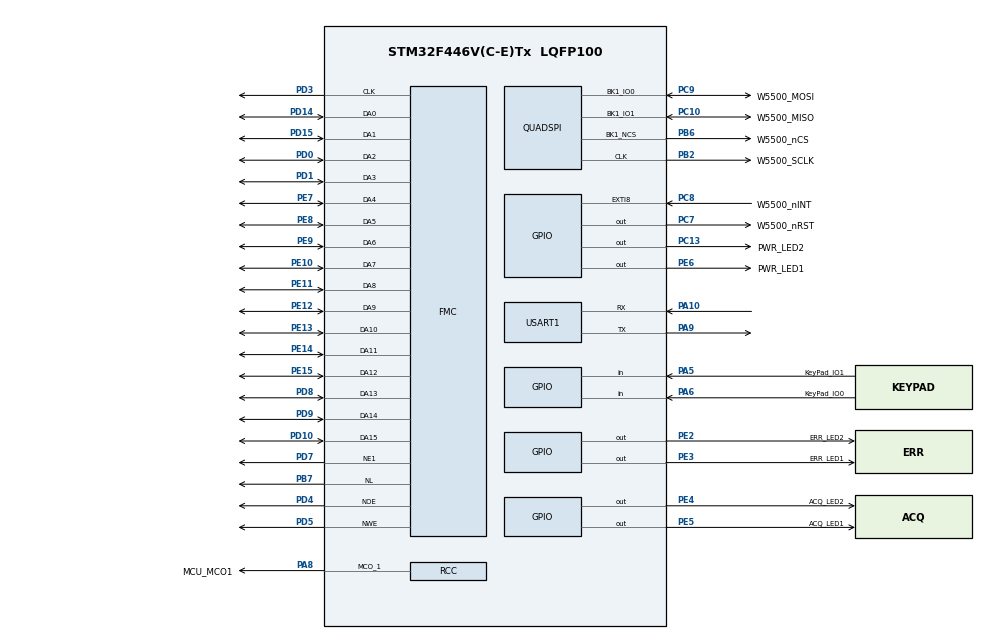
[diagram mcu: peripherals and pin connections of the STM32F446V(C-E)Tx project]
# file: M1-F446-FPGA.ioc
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Dma.MEMTOMEM.0.Direction=DMA_MEMORY_TO_MEMORY
Dma.MEMTOMEM.0.FIFOMode=DMA_FIFOMODE_ENABLE
Dma.MEMTOMEM.0.FIFOThreshold=DMA_FIFO_THRESHOLD_FULL
Dma.MEMTOMEM.0.Instance=DMA2_Stream0
Dma.MEMTOMEM.0.MemBurst=DMA_MBURST_INC8
Dma.MEMTOMEM.0.MemDataAlignment=DMA_MDATAALIGN_HALFWORD
Dma.MEMTOMEM.0.MemInc=DMA_MINC_ENABLE
Dma.MEMTOMEM.0.Mode=DMA_NORMAL
Dma.MEMTOMEM.0.PeriphBurst=DMA_PBURST_INC8
Dma.MEMTOMEM.0.PeriphDataAlignment=DMA_PDATAALIGN_HALFWORD
Dma.MEMTOMEM.0.PeriphInc=DMA_PINC_ENABLE
Dma.MEMTOMEM.0.Priority=DMA_PRIORITY_HIGH
Dma.MEMTOMEM.1.Direction=DMA_MEMORY_TO_MEMORY
Dma.MEMTOMEM.1.FIFOMode=DMA_FIFOMODE_ENABLE
Dma.MEMTOMEM.1.FIFOThreshold=DMA_FIFO_THRESHOLD_FULL
Dma.MEMTOMEM.1.Instance=DMA2_Stream1
Dma.MEMTOMEM.1.MemBurst=DMA_MBURST_INC8
Dma.MEMTOMEM.1.MemDataAlignment=DMA_MDATAALIGN_HALFWORD
Dma.MEMTOMEM.1.MemInc=DMA_MINC_ENABLE
Dma.MEMTOMEM.1.Mode=DMA_NORMAL
Dma.MEMTOMEM.1.PeriphBurst=DMA_PBURST_INC8
Dma.MEMTOMEM.1.PeriphDataAlignment=DMA_PDATAALIGN_HALFWORD
Dma.MEMTOMEM.1.PeriphInc=DMA_PINC_ENABLE
Dma.MEMTOMEM.1.Priority=DMA_PRIORITY_HIGH
Dma.QUADSPI.2.Direction=DMA_MEMORY_TO_PERIPH
Dma.QUADSPI.2.FIFOMode=DMA_FIFOMODE_DISABLE
Dma.QUADSPI.2.Instance=DMA2_Stream7
Dma.QUADSPI.2.MemDataAlignment=DMA_MDATAALIGN_BYTE
Dma.QUADSPI.2.MemInc=DMA_MINC_ENABLE
Dma.QUADSPI.2.Mode=DMA_NORMAL
Dma.QUADSPI.2.PeriphDataAlignment=DMA_PDATAALIGN_BYTE
Dma.QUADSPI.2.PeriphInc=DMA_PINC_DISABLE
Dma.QUADSPI.2.Priority=DMA_PRIORITY_LOW
Dma.Request0=MEMTOMEM
Dma.Request1=MEMTOMEM
Dma.Request2=QUADSPI
FMC.BusTurnAroundDuration1=4
FMC.CLKDivision1=2
FMC.WriteOperation1=FMC_WRITE_OPERATION_ENABLE
Mcu.Family=STM32F4
Mcu.Name=STM32F446V(C-E)Tx
Mcu.Package=LQFP100
NVIC.PriorityGroup=NVIC_PRIORITYGROUP_4
PA10.Mode=Asynchronous
PA10.Signal=USART1_RX
PA5.GPIO_Label=KeyPad_IO1
PA5.Signal=GPIO_Input
PA6.GPIO_Label=KeyPad_IO0
PA6.Signal=GPIO_Input
PA8.GPIO_Label=MCU_MCO1
PA8.GPIO_Speed=GPIO_SPEED_FREQ_HIGH
PA8.Mode=Clock-out-1
PA8.Signal=RCC_MCO_1
PA9.Mode=Asynchronous
PA9.Signal=USART1_TX
PB2.GPIO_Label=W5500_SCLK
PB2.Mode=Single Bank 1 2IOs
PB2.Signal=QUADSPI_CLK
PB6.GPIO_Label=W5500_nCS
PB6.Mode=Single Bank 1 2IOs
PB6.Signal=QUADSPI_BK1_NCS
PB7.Signal=FMC_NL
PC10.GPIO_Label=W5500_MISO
PC10.Mode=Single Bank 1 2IOs
PC10.Signal=QUADSPI_BK1_IO1
PC13.GPIO_Label=PWR_LED2
PC13.Signal=GPIO_Output
PC14-OSC32_IN.Mode=LSE-External-Oscillator
PC14-OSC32_IN.Signal=RCC_OSC32_IN
PC15-OSC32_OUT.Mode=LSE-External-Oscillator
PC15-OSC32_OUT.Signal=RCC_OSC32_OUT
PC7.GPIO_Label=W5500_nRST
PC7.PinState=GPIO_PIN_SET
PC7.Signal=GPIO_Output
PC8.GPIO_Label=W5500_nINT
PC8.GPIO_ModeDefaultEXTI=GPIO_MODE_IT_FALLING
PC8.Signal=GPXTI8
PC9.GPIO_Label=W5500_MOSI
PC9.Mode=Single Bank 1 2IOs
PC9.Signal=QUADSPI_BK1_IO0
PD0.Mode=16b-da1
PD0.Signal=FMC_DA2
PD1.Mode=16b-da1
PD1.Signal=FMC_DA3
PD10.Mode=16b-da1
PD10.Signal=FMC_DA15
PD14.Mode=16b-da1
PD14.Signal=FMC_DA0
PD15.Mode=16b-da1
PD15.Signal=FMC_DA1
PD3.Mode=BurstReadWrite1
PD3.Signal=FMC_CLK
PD4.Mode=MuxedPsram1
PD4.Signal=FMC_NOE
PD5.Mode=MuxedPsram1
PD5.Signal=FMC_NWE
PD7.Mode=NorPsramChipSelect1_1
PD7.Signal=FMC_NE1
PD8.Mode=16b-da1
PD8.Signal=FMC_DA13
PD9.Mode=16b-da1
PD9.Signal=FMC_DA14
PE10.Mode=16b-da1
PE10.Signal=FMC_DA7
PE11.Mode=16b-da1
PE11.Signal=FMC_DA8
PE12.Mode=16b-da1
PE12.Signal=FMC_DA9
PE13.Mode=16b-da1
PE13.Signal=FMC_DA10
PE14.Mode=16b-da1
PE14.Signal=FMC_DA11
PE15.Mode=16b-da1
PE15.Signal=FMC_DA12
PE2.GPIO_Label=ERR_LED2
PE2.Signal=GPIO_Output
PE3.GPIO_Label=ERR_LED1
PE3.Signal=GPIO_Output
PE4.GPIO_Label=ACQ_LED2
PE4.Signal=GPIO_Output
PE5.GPIO_Label=ACQ_LED1
PE5.Signal=GPIO_Output
PE6.GPIO_Label=PWR_LED1
PE6.Signal=GPIO_Output
PE7.Mode=16b-da1
PE7.Signal=FMC_DA4
PE8.Mode=16b-da1
PE8.Signal=FMC_DA5
PE9.Mode=16b-da1
PE9.Signal=FMC_DA6
PH0-OSC_IN.Mode=HSE-External-Oscillator
PH0-OSC_IN.Signal=RCC_OSC_IN
PH1-OSC_OUT.Mode=HSE-External-Oscillator
PH1-OSC_OUT.Signal=RCC_OSC_OUT
ProjectManager.HeapSize=0x200
ProjectManager.StackSize=0x400
ProjectManager.TargetToolchain=MDK-ARM V5.27
QUADSPI.ChipSelectHighTime=QSPI_CS_HIGH_TIME_4_CYCLE
QUADSPI.ClockPrescaler=3
QUADSPI.FifoThreshold=9
QUADSPI.FlashSize=16
RCC.AHBFreq_Value=160000000
RCC.APB1CLKDivider=RCC_HCLK_DIV4
RCC.APB1Freq_Value=40000000
RCC.APB1TimFreq_Value=80000000
RCC.APB2CLKDivider=RCC_HCLK_DIV2
RCC.APB2Freq_Value=80000000
RCC.APB2TimFreq_Value=160000000
RCC.CortexFreq_Value=160000000
RCC.HCLKFreq_Value=160000000
RCC.HSE_VALUE=16000000
RCC.PLLN=320
RCC.PLLSourceVirtual=RCC_PLLSOURCE_HSE
RCC.RCC_TIM_PRescaler_Selection=RCC_TIMPRES_DESACTIVATED
RCC.SYSCLKFreq_VALUE=160000000
RCC.SYSCLKSource=RCC_SYSCLKSOURCE_PLLCLK
RCC.USBFreq_Value=160000000
RCC.VCOOutputFreq_Value=320000000
SH.FMC_NL.0=FMC_NL,AddressValid1
USART1.VirtualMode=VM_ASYNC
board=custom

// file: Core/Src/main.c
/* USER CODE BEGIN Header */
/**
  ******************************************************************************
  * @file           : main.c
  * @brief          : Main program body
  ******************************************************************************
  * @attention
  *
  * <h2><center>&copy; Copyright (c) 2022 STMicroelectronics.
  * All rights reserved.</center></h2>
  *
  * This software component is licensed by ST under BSD 3-Clause license,
  * the "License"; You may not use this file except in compliance with the
  * License. You may obtain a copy of the License at:
  *                        opensource.org/licenses/BSD-3-Clause
  *
  ******************************************************************************
  */
/* USER CODE END Header */
#include "main.h"

/* USER CODE BEGIN Includes */
#include "w5500_service.h"
/* USER CODE END Includes */

QSPI_HandleTypeDef hqspi;
DMA_HandleTypeDef hdma_quadspi;

SRAM_HandleTypeDef hsram1;

/* USER CODE BEGIN PV */
uint32_t SYS_Event;							//!< 系统状态事件
/* USER CODE END PV */

void SystemClock_Config(void);
static void MX_GPIO_Init(void);
static void MX_DMA_Init(void);
static void MX_FMC_Init(void);
static void MX_USART1_UART_Init(void);
static void MX_QUADSPI_Init(void);

int main(void)
{

  /* MCU Configuration--------------------------------------------------------*/

  /* Reset of all peripherals, Initializes the Flash interface and the Systick. */
  HAL_Init();

  /* Configure the system clock */
  SystemClock_Config();

  /* Initialize all configured peripherals */
  MX_GPIO_Init();
  MX_DMA_Init();
  MX_FMC_Init();
  MX_USART1_UART_Init();
  MX_QUADSPI_Init();
  /* USER CODE BEGIN 2 */

	PWR_LED1_ON;	//设备通电状态指示
	PWR_LED2_OFF;
	ACQ_LED1_OFF; //设备采样状态指示
	ACQ_LED2_OFF; //设备事件接收指示 （收发完成一次亮灭）
	ERR_LED1_OFF;
	ERR_LED2_OFF; //设备运行状态指示
	W5500_Init(); //W5500初始化，配置Socket
  /* USER CODE END 2 */

  /* Infinite loop */
  while (1)
  {

  }
}

void SystemClock_Config(void)
{
  LL_FLASH_SetLatency(LL_FLASH_LATENCY_5);
  while(LL_FLASH_GetLatency()!= LL_FLASH_LATENCY_5)
  {
  }
  LL_PWR_SetRegulVoltageScaling(LL_PWR_REGU_VOLTAGE_SCALE1);
  LL_PWR_DisableOverDriveMode();
  LL_RCC_HSE_Enable();

   /* Wait till HSE is ready */
  while(LL_RCC_HSE_IsReady() != 1)
  {

  }
  LL_RCC_HSI_SetCalibTrimming(16);
  LL_RCC_HSI_Enable();

   /* Wait till HSI is ready */
  while(LL_RCC_HSI_IsReady() != 1)
  {

  }
  LL_RCC_PLL_ConfigDomain_SYS(LL_RCC_PLLSOURCE_HSE, LL_RCC_PLLM_DIV_16, 320, LL_RCC_PLLP_DIV_2);
  LL_RCC_PLL_Enable();

   /* Wait till PLL is ready */
  while(LL_RCC_PLL_IsReady() != 1)
  {

  }
  LL_RCC_SetAHBPrescaler(LL_RCC_SYSCLK_DIV_1);
  LL_RCC_SetAPB1Prescaler(LL_RCC_APB1_DIV_4);
  LL_RCC_SetAPB2Prescaler(LL_RCC_APB2_DIV_2);
  LL_RCC_SetSysClkSource(LL_RCC_SYS_CLKSOURCE_PLL);

   /* Wait till System clock is ready */
  while(LL_RCC_GetSysClkSource() != LL_RCC_SYS_CLKSOURCE_STATUS_PLL)
  {

  }
  LL_SetSystemCoreClock(160000000);

   /* Update the time base */
  if (HAL_InitTick (TICK_INT_PRIORITY) != HAL_OK)
  {
    Error_Handler();
  }
  LL_RCC_ConfigMCO(LL_RCC_MCO1SOURCE_HSI, LL_RCC_MCO1_DIV_1);
  LL_RCC_SetTIMPrescaler(LL_RCC_TIM_PRESCALER_TWICE);
}

static void MX_QUADSPI_Init(void)
{

  /* QUADSPI parameter configuration*/
  hqspi.Instance = QUADSPI;
  hqspi.Init.ClockPrescaler = 3;
  hqspi.Init.FifoThreshold = 9;
  hqspi.Init.SampleShifting = QSPI_SAMPLE_SHIFTING_NONE;
  hqspi.Init.FlashSize = 16;
  hqspi.Init.ChipSelectHighTime = QSPI_CS_HIGH_TIME_4_CYCLE;
  hqspi.Init.ClockMode = QSPI_CLOCK_MODE_0;
  hqspi.Init.FlashID = QSPI_FLASH_ID_1;
  hqspi.Init.DualFlash = QSPI_DUALFLASH_DISABLE;
  if (HAL_QSPI_Init(&hqspi) != HAL_OK)
  {
    Error_Handler();
  }

}

static void MX_USART1_UART_Init(void)
{

  LL_USART_InitTypeDef USART_InitStruct = {0};

  LL_GPIO_InitTypeDef GPIO_InitStruct = {0};

  /* Peripheral clock enable */
  LL_APB2_GRP1_EnableClock(LL_APB2_GRP1_PERIPH_USART1);

  LL_AHB1_GRP1_EnableClock(LL_AHB1_GRP1_PERIPH_GPIOA);
  /**USART1 GPIO Configuration
  PA9   ------> USART1_TX
  PA10   ------> USART1_RX
  */
  GPIO_InitStruct.Pin = LL_GPIO_PIN_9|LL_GPIO_PIN_10;
  GPIO_InitStruct.Mode = LL_GPIO_MODE_ALTERNATE;
  GPIO_InitStruct.Speed = LL_GPIO_SPEED_FREQ_VERY_HIGH;
  GPIO_InitStruct.OutputType = LL_GPIO_OUTPUT_PUSHPULL;
  GPIO_InitStruct.Pull = LL_GPIO_PULL_NO;
  GPIO_InitStruct.Alternate = LL_GPIO_AF_7;
  LL_GPIO_Init(GPIOA, &GPIO_InitStruct);

  USART_InitStruct.BaudRate = 115200;
  USART_InitStruct.DataWidth = LL_USART_DATAWIDTH_8B;
  USART_InitStruct.StopBits = LL_USART_STOPBITS_1;
  USART_InitStruct.Parity = LL_USART_PARITY_NONE;
  USART_InitStruct.TransferDirection = LL_USART_DIRECTION_TX_RX;
  USART_InitStruct.HardwareFlowControl = LL_USART_HWCONTROL_NONE;
  USART_InitStruct.OverSampling = LL_USART_OVERSAMPLING_16;
  LL_USART_Init(USART1, &USART_InitStruct);
  LL_USART_ConfigAsyncMode(USART1);
  LL_USART_Enable(USART1);

}

static void MX_DMA_Init(void)
{

  /* Init with LL driver */
  /* DMA controller clock enable */
  LL_AHB1_GRP1_EnableClock(LL_AHB1_GRP1_PERIPH_DMA2);

  /* Configure DMA request MEMTOMEM_DMA2_Stream0 */

  /* Select channel */
  LL_DMA_SetChannelSelection(DMA2, LL_DMA_STREAM_0, LL_DMA_CHANNEL_0);

  /* Set transfer direction */
  LL_DMA_SetDataTransferDirection(DMA2, LL_DMA_STREAM_0, LL_DMA_DIRECTION_MEMORY_TO_MEMORY);

  /* Set priority level */
  LL_DMA_SetStreamPriorityLevel(DMA2, LL_DMA_STREAM_0, LL_DMA_PRIORITY_HIGH);

  /* Set DMA mode */
  LL_DMA_SetMode(DMA2, LL_DMA_STREAM_0, LL_DMA_MODE_NORMAL);

  /* Set peripheral increment mode */
  LL_DMA_SetPeriphIncMode(DMA2, LL_DMA_STREAM_0, LL_DMA_PERIPH_INCREMENT);

  /* Set memory increment mode */
  LL_DMA_SetMemoryIncMode(DMA2, LL_DMA_STREAM_0, LL_DMA_MEMORY_INCREMENT);

  /* Set peripheral data width */
  LL_DMA_SetPeriphSize(DMA2, LL_DMA_STREAM_0, LL_DMA_PDATAALIGN_HALFWORD);

  /* Set memory data width */
  LL_DMA_SetMemorySize(DMA2, LL_DMA_STREAM_0, LL_DMA_MDATAALIGN_HALFWORD);

  /* Enable FIFO mode */
  LL_DMA_EnableFifoMode(DMA2, LL_DMA_STREAM_0);

  /* Set FIFO threshold */
  LL_DMA_SetFIFOThreshold(DMA2, LL_DMA_STREAM_0, LL_DMA_FIFOTHRESHOLD_FULL);

  /* Set memory burst size */
  LL_DMA_SetMemoryBurstxfer(DMA2, LL_DMA_STREAM_0, LL_DMA_MBURST_INC8);

  /* Set peripheral burst size */
  LL_DMA_SetPeriphBurstxfer(DMA2, LL_DMA_STREAM_0, LL_DMA_PBURST_INC8);

  /* Configure DMA request MEMTOMEM_DMA2_Stream1 */

  /* Select channel */
  LL_DMA_SetChannelSelection(DMA2, LL_DMA_STREAM_1, LL_DMA_CHANNEL_0);

  /* Set transfer direction */
  LL_DMA_SetDataTransferDirection(DMA2, LL_DMA_STREAM_1, LL_DMA_DIRECTION_MEMORY_TO_MEMORY);

  /* Set priority level */
  LL_DMA_SetStreamPriorityLevel(DMA2, LL_DMA_STREAM_1, LL_DMA_PRIORITY_HIGH);

  /* Set DMA mode */
  LL_DMA_SetMode(DMA2, LL_DMA_STREAM_1, LL_DMA_MODE_NORMAL);

  /* Set peripheral increment mode */
  LL_DMA_SetPeriphIncMode(DMA2, LL_DMA_STREAM_1, LL_DMA_PERIPH_INCREMENT);

  /* Set memory increment mode */
  LL_DMA_SetMemoryIncMode(DMA2, LL_DMA_STREAM_1, LL_DMA_MEMORY_INCREMENT);

  /* Set peripheral data width */
  LL_DMA_SetPeriphSize(DMA2, LL_DMA_STREAM_1, LL_DMA_PDATAALIGN_HALFWORD);

  /* Set memory data width */
  LL_DMA_SetMemorySize(DMA2, LL_DMA_STREAM_1, LL_DMA_MDATAALIGN_HALFWORD);

  /* Enable FIFO mode */
  LL_DMA_EnableFifoMode(DMA2, LL_DMA_STREAM_1);

  /* Set FIFO threshold */
  LL_DMA_SetFIFOThreshold(DMA2, LL_DMA_STREAM_1, LL_DMA_FIFOTHRESHOLD_FULL);

  /* Set memory burst size */
  LL_DMA_SetMemoryBurstxfer(DMA2, LL_DMA_STREAM_1, LL_DMA_MBURST_INC8);

  /* Set peripheral burst size */
  LL_DMA_SetPeriphBurstxfer(DMA2, LL_DMA_STREAM_1, LL_DMA_PBURST_INC8);

}

/* FMC initialization function */
static void MX_FMC_Init(void)
{

  FMC_NORSRAM_TimingTypeDef Timing = {0};

  /** Perform the SRAM1 memory initialization sequence
  */
  hsram1.Instance = FMC_NORSRAM_DEVICE;
  hsram1.Extended = FMC_NORSRAM_EXTENDED_DEVICE;
  /* hsram1.Init */
  hsram1.Init.NSBank = FMC_NORSRAM_BANK1;
  hsram1.Init.DataAddressMux = FMC_DATA_ADDRESS_MUX_ENABLE;
  hsram1.Init.MemoryType = FMC_MEMORY_TYPE_PSRAM;
  hsram1.Init.MemoryDataWidth = FMC_NORSRAM_MEM_BUS_WIDTH_16;
  hsram1.Init.BurstAccessMode = FMC_BURST_ACCESS_MODE_ENABLE;
  hsram1.Init.WaitSignalPolarity = FMC_WAIT_SIGNAL_POLARITY_LOW;
  hsram1.Init.WaitSignalActive = FMC_WAIT_TIMING_BEFORE_WS;
  hsram1.Init.WriteOperation = FMC_WRITE_OPERATION_ENABLE;
  hsram1.Init.WaitSignal = FMC_WAIT_SIGNAL_DISABLE;
  hsram1.Init.ExtendedMode = FMC_EXTENDED_MODE_DISABLE;
  hsram1.Init.AsynchronousWait = FMC_ASYNCHRONOUS_WAIT_DISABLE;
  hsram1.Init.WriteBurst = FMC_WRITE_BURST_ENABLE;
  hsram1.Init.ContinuousClock = FMC_CONTINUOUS_CLOCK_SYNC_ONLY;
  hsram1.Init.WriteFifo = FMC_WRITE_FIFO_ENABLE;
  hsram1.Init.PageSize = FMC_PAGE_SIZE_NONE;
  /* Timing */
  Timing.AddressSetupTime = 15;
  Timing.AddressHoldTime = 15;
  Timing.DataSetupTime = 255;
  Timing.BusTurnAroundDuration = 4;
  Timing.CLKDivision = 2;
  Timing.DataLatency = 2;
  Timing.AccessMode = FMC_ACCESS_MODE_A;
  /* ExtTiming */

  if (HAL_SRAM_Init(&hsram1, &Timing, NULL) != HAL_OK)
  {
    Error_Handler( );
  }

}

static void MX_GPIO_Init(void)
{
  LL_EXTI_InitTypeDef EXTI_InitStruct = {0};
  LL_GPIO_InitTypeDef GPIO_InitStruct = {0};

  /* GPIO Ports Clock Enable */
  LL_AHB1_GRP1_EnableClock(LL_AHB1_GRP1_PERIPH_GPIOE);
  LL_AHB1_GRP1_EnableClock(LL_AHB1_GRP1_PERIPH_GPIOC);
  LL_AHB1_GRP1_EnableClock(LL_AHB1_GRP1_PERIPH_GPIOH);
  LL_AHB1_GRP1_EnableClock(LL_AHB1_GRP1_PERIPH_GPIOA);
  LL_AHB1_GRP1_EnableClock(LL_AHB1_GRP1_PERIPH_GPIOB);
  LL_AHB1_GRP1_EnableClock(LL_AHB1_GRP1_PERIPH_GPIOD);

  /**/
  LL_GPIO_ResetOutputPin(GPIOE, ERR_LED2_Pin|ERR_LED1_Pin|ACQ_LED2_Pin|ACQ_LED1_Pin
                          |PWR_LED1_Pin);

  /**/
  LL_GPIO_ResetOutputPin(PWR_LED2_GPIO_Port, PWR_LED2_Pin);

  /**/
  LL_GPIO_SetOutputPin(W5500_nRST_GPIO_Port, W5500_nRST_Pin);

  /**/
  GPIO_InitStruct.Pin = ERR_LED2_Pin|ERR_LED1_Pin|ACQ_LED2_Pin|ACQ_LED1_Pin
                          |PWR_LED1_Pin;
  GPIO_InitStruct.Mode = LL_GPIO_MODE_OUTPUT;
  GPIO_InitStruct.Speed = LL_GPIO_SPEED_FREQ_LOW;
  GPIO_InitStruct.OutputType = LL_GPIO_OUTPUT_PUSHPULL;
  GPIO_InitStruct.Pull = LL_GPIO_PULL_NO;
  LL_GPIO_Init(GPIOE, &GPIO_InitStruct);

  /**/
  GPIO_InitStruct.Pin = PWR_LED2_Pin|W5500_nRST_Pin;
  GPIO_InitStruct.Mode = LL_GPIO_MODE_OUTPUT;
  GPIO_InitStruct.Speed = LL_GPIO_SPEED_FREQ_LOW;
  GPIO_InitStruct.OutputType = LL_GPIO_OUTPUT_PUSHPULL;
  GPIO_InitStruct.Pull = LL_GPIO_PULL_NO;
  LL_GPIO_Init(GPIOC, &GPIO_InitStruct);

  /**/
  GPIO_InitStruct.Pin = KeyPad_IO1_Pin|KeyPad_IO0_Pin;
  GPIO_InitStruct.Mode = LL_GPIO_MODE_INPUT;
  GPIO_InitStruct.Pull = LL_GPIO_PULL_NO;
  LL_GPIO_Init(GPIOA, &GPIO_InitStruct);

  /**/
  GPIO_InitStruct.Pin = MCU_MCO1_Pin;
  GPIO_InitStruct.Mode = LL_GPIO_MODE_ALTERNATE;
  GPIO_InitStruct.Speed = LL_GPIO_SPEED_FREQ_HIGH;
  GPIO_InitStruct.OutputType = LL_GPIO_OUTPUT_PUSHPULL;
  GPIO_InitStruct.Pull = LL_GPIO_PULL_NO;
  GPIO_InitStruct.Alternate = LL_GPIO_AF_0;
  LL_GPIO_Init(MCU_MCO1_GPIO_Port, &GPIO_InitStruct);

  /**/
  LL_SYSCFG_SetEXTISource(LL_SYSCFG_EXTI_PORTC, LL_SYSCFG_EXTI_LINE8);

  /**/
  EXTI_InitStruct.Line_0_31 = LL_EXTI_LINE_8;
  EXTI_InitStruct.LineCommand = ENABLE;
  EXTI_InitStruct.Mode = LL_EXTI_MODE_IT;
  EXTI_InitStruct.Trigger = LL_EXTI_TRIGGER_FALLING;
  LL_EXTI_Init(&EXTI_InitStruct);

  /**/
  LL_GPIO_SetPinPull(W5500_nINT_GPIO_Port, W5500_nINT_Pin, LL_GPIO_PULL_NO);

  /**/
  LL_GPIO_SetPinMode(W5500_nINT_GPIO_Port, W5500_nINT_Pin, LL_GPIO_MODE_INPUT);

}

void Error_Handler(void)
{
  __disable_irq();
  while (1)
  {
  }
}

/************************ (C) COPYRIGHT STMicroelectronics *****END OF FILE****/
